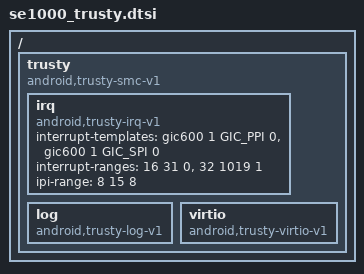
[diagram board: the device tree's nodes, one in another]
/ {
	trusty {
		compatible = "android,trusty-smc-v1";
		ranges;
		#address-cells = <2>;
		#size-cells = <2>;

		irq {
			compatible = "android,trusty-irq-v1";
			interrupt-templates = <&gic600 1 GIC_PPI 0>,
					      <&gic600 1 GIC_SPI 0>;
			interrupt-ranges = <16  31 0>,
					   <32 1019 1>;
			ipi-range = <8 15 8>;
		};

		log {
			compatible = "android,trusty-log-v1";
		};

		virtio {
			compatible = "android,trusty-virtio-v1";
		};

	};
};
